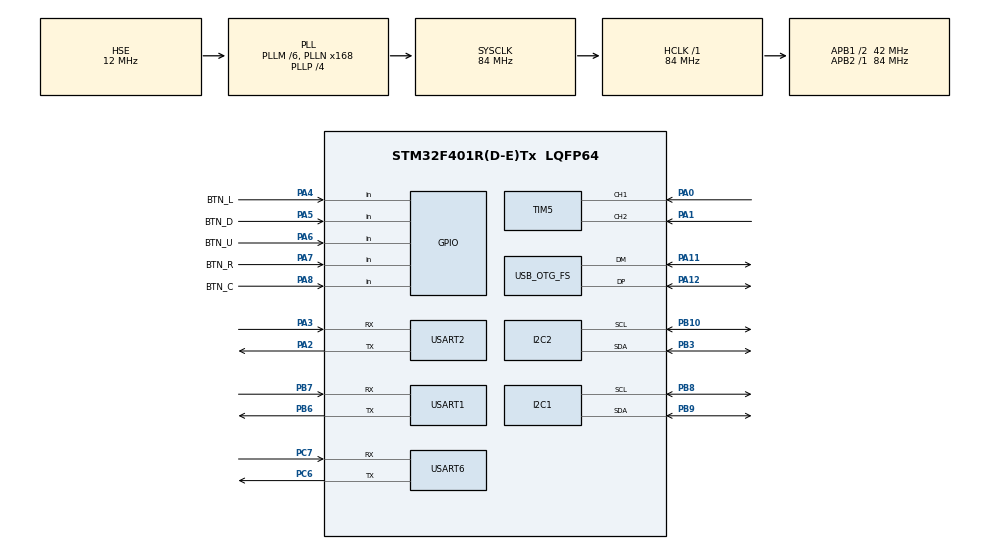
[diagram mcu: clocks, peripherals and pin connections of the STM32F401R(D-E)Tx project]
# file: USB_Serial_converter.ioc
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Dma.I2C1_RX.5.Direction=DMA_PERIPH_TO_MEMORY
Dma.I2C1_RX.5.FIFOMode=DMA_FIFOMODE_DISABLE
Dma.I2C1_RX.5.Instance=DMA1_Stream0
Dma.I2C1_RX.5.MemDataAlignment=DMA_MDATAALIGN_BYTE
Dma.I2C1_RX.5.MemInc=DMA_MINC_ENABLE
Dma.I2C1_RX.5.Mode=DMA_NORMAL
Dma.I2C1_RX.5.PeriphDataAlignment=DMA_PDATAALIGN_BYTE
Dma.I2C1_RX.5.PeriphInc=DMA_PINC_DISABLE
Dma.I2C1_RX.5.Priority=DMA_PRIORITY_LOW
Dma.I2C1_TX.0.Direction=DMA_MEMORY_TO_PERIPH
Dma.I2C1_TX.0.FIFOMode=DMA_FIFOMODE_DISABLE
Dma.I2C1_TX.0.Instance=DMA1_Stream6
Dma.I2C1_TX.0.MemDataAlignment=DMA_MDATAALIGN_BYTE
Dma.I2C1_TX.0.MemInc=DMA_MINC_ENABLE
Dma.I2C1_TX.0.Mode=DMA_NORMAL
Dma.I2C1_TX.0.PeriphDataAlignment=DMA_PDATAALIGN_BYTE
Dma.I2C1_TX.0.PeriphInc=DMA_PINC_DISABLE
Dma.I2C1_TX.0.Priority=DMA_PRIORITY_LOW
Dma.I2C2_RX.6.Direction=DMA_PERIPH_TO_MEMORY
Dma.I2C2_RX.6.FIFOMode=DMA_FIFOMODE_DISABLE
Dma.I2C2_RX.6.Instance=DMA1_Stream2
Dma.I2C2_RX.6.MemDataAlignment=DMA_MDATAALIGN_BYTE
Dma.I2C2_RX.6.MemInc=DMA_MINC_ENABLE
Dma.I2C2_RX.6.Mode=DMA_NORMAL
Dma.I2C2_RX.6.PeriphDataAlignment=DMA_PDATAALIGN_BYTE
Dma.I2C2_RX.6.PeriphInc=DMA_PINC_DISABLE
Dma.I2C2_RX.6.Priority=DMA_PRIORITY_LOW
Dma.I2C2_TX.1.Direction=DMA_MEMORY_TO_PERIPH
Dma.I2C2_TX.1.FIFOMode=DMA_FIFOMODE_DISABLE
Dma.I2C2_TX.1.Instance=DMA1_Stream7
Dma.I2C2_TX.1.MemDataAlignment=DMA_MDATAALIGN_BYTE
Dma.I2C2_TX.1.MemInc=DMA_MINC_ENABLE
Dma.I2C2_TX.1.Mode=DMA_NORMAL
Dma.I2C2_TX.1.PeriphDataAlignment=DMA_PDATAALIGN_BYTE
Dma.I2C2_TX.1.PeriphInc=DMA_PINC_DISABLE
Dma.I2C2_TX.1.Priority=DMA_PRIORITY_LOW
Dma.Request0=I2C1_TX
Dma.Request1=I2C2_TX
Dma.Request2=USART1_RX
Dma.Request3=USART2_RX
Dma.Request4=USART6_RX
Dma.Request5=I2C1_RX
Dma.Request6=I2C2_RX
Dma.USART1_RX.2.Direction=DMA_PERIPH_TO_MEMORY
Dma.USART1_RX.2.FIFOMode=DMA_FIFOMODE_DISABLE
Dma.USART1_RX.2.Instance=DMA2_Stream2
Dma.USART1_RX.2.MemDataAlignment=DMA_MDATAALIGN_BYTE
Dma.USART1_RX.2.MemInc=DMA_MINC_ENABLE
Dma.USART1_RX.2.Mode=DMA_CIRCULAR
Dma.USART1_RX.2.PeriphDataAlignment=DMA_PDATAALIGN_BYTE
Dma.USART1_RX.2.PeriphInc=DMA_PINC_DISABLE
Dma.USART1_RX.2.Priority=DMA_PRIORITY_LOW
Dma.USART2_RX.3.Direction=DMA_PERIPH_TO_MEMORY
Dma.USART2_RX.3.FIFOMode=DMA_FIFOMODE_DISABLE
Dma.USART2_RX.3.Instance=DMA1_Stream5
Dma.USART2_RX.3.MemDataAlignment=DMA_MDATAALIGN_BYTE
Dma.USART2_RX.3.MemInc=DMA_MINC_ENABLE
Dma.USART2_RX.3.Mode=DMA_CIRCULAR
Dma.USART2_RX.3.PeriphDataAlignment=DMA_PDATAALIGN_BYTE
Dma.USART2_RX.3.PeriphInc=DMA_PINC_DISABLE
Dma.USART2_RX.3.Priority=DMA_PRIORITY_LOW
Dma.USART6_RX.4.Direction=DMA_PERIPH_TO_MEMORY
Dma.USART6_RX.4.FIFOMode=DMA_FIFOMODE_DISABLE
Dma.USART6_RX.4.Instance=DMA2_Stream1
Dma.USART6_RX.4.MemDataAlignment=DMA_MDATAALIGN_BYTE
Dma.USART6_RX.4.MemInc=DMA_MINC_ENABLE
Dma.USART6_RX.4.Mode=DMA_CIRCULAR
Dma.USART6_RX.4.PeriphDataAlignment=DMA_PDATAALIGN_BYTE
Dma.USART6_RX.4.PeriphInc=DMA_PINC_DISABLE
Dma.USART6_RX.4.Priority=DMA_PRIORITY_LOW
I2C1.DutyCycle=I2C_DUTYCYCLE_2
I2C1.I2C_Mode=I2C_Fast
I2C2.I2C_Mode=I2C_Fast
Mcu.Family=STM32F4
Mcu.Name=STM32F401R(D-E)Tx
Mcu.Package=LQFP64
NVIC.DMA1_Stream0_IRQn=true\:0\:0\:false\:false\:true\:false\:true\:true
NVIC.DMA1_Stream2_IRQn=true\:0\:0\:false\:false\:true\:false\:true\:true
NVIC.DMA1_Stream5_IRQn=true\:0\:0\:false\:false\:true\:false\:true\:true
NVIC.DMA1_Stream6_IRQn=true\:0\:0\:false\:false\:true\:false\:true\:true
NVIC.DMA1_Stream7_IRQn=true\:0\:0\:false\:false\:true\:false\:true\:true
NVIC.DMA2_Stream1_IRQn=true\:0\:0\:false\:false\:true\:false\:true\:true
NVIC.DMA2_Stream2_IRQn=true\:0\:0\:false\:false\:true\:false\:true\:true
NVIC.I2C1_ER_IRQn=true\:6\:0\:true\:false\:true\:true\:true\:true
NVIC.I2C1_EV_IRQn=true\:6\:0\:true\:false\:true\:true\:true\:true
NVIC.I2C2_ER_IRQn=true\:6\:0\:true\:false\:true\:true\:true\:true
NVIC.I2C2_EV_IRQn=true\:6\:0\:true\:false\:true\:true\:true\:true
NVIC.OTG_FS_IRQn=true\:0\:0\:false\:false\:true\:false\:true\:true
NVIC.PriorityGroup=NVIC_PRIORITYGROUP_4
NVIC.USART1_IRQn=true\:6\:0\:true\:false\:true\:true\:true\:true
NVIC.USART2_IRQn=true\:6\:0\:true\:false\:true\:true\:true\:true
NVIC.USART6_IRQn=true\:6\:0\:true\:false\:true\:true\:true\:true
PA0-WKUP.Signal=S_TIM5_CH1
PA1.Signal=S_TIM5_CH2
PA11.Mode=Device_Only
PA11.Signal=USB_OTG_FS_DM
PA12.Mode=Device_Only
PA12.Signal=USB_OTG_FS_DP
PA13.Mode=Serial_Wire
PA13.Signal=SYS_JTMS-SWDIO
PA14.Mode=Serial_Wire
PA14.Signal=SYS_JTCK-SWCLK
PA2.Mode=Asynchronous
PA2.Signal=USART2_TX
PA3.Mode=Asynchronous
PA3.Signal=USART2_RX
PA4.GPIO_Label=BTN_L
PA4.Signal=GPIO_Input
PA5.GPIO_Label=BTN_D
PA5.Signal=GPIO_Input
PA6.GPIO_Label=BTN_U
PA6.Signal=GPIO_Input
PA7.GPIO_Label=BTN_R
PA7.Signal=GPIO_Input
PA8.GPIO_Label=BTN_C
PA8.Signal=GPIO_Input
PB10.GPIO_Pu=GPIO_PULLUP
PB10.Mode=I2C
PB10.Signal=I2C2_SCL
PB3.GPIO_Pu=GPIO_PULLUP
PB3.Mode=I2C
PB3.Signal=I2C2_SDA
PB6.Mode=Asynchronous
PB6.Signal=USART1_TX
PB7.Mode=Asynchronous
PB7.Signal=USART1_RX
PB8.GPIO_Pu=GPIO_PULLUP
PB8.Mode=I2C
PB8.Signal=I2C1_SCL
PB9.GPIO_Pu=GPIO_PULLUP
PB9.Mode=I2C
PB9.Signal=I2C1_SDA
PC6.Mode=Asynchronous
PC6.Signal=USART6_TX
PC7.Mode=Asynchronous
PC7.Signal=USART6_RX
PH0\ -\ OSC_IN.Mode=HSE-External-Oscillator
PH0\ -\ OSC_IN.Signal=RCC_OSC_IN
PH1\ -\ OSC_OUT.Mode=HSE-External-Oscillator
PH1\ -\ OSC_OUT.Signal=RCC_OSC_OUT
ProjectManager.HeapSize=0x200
ProjectManager.StackSize=0x400
ProjectManager.TargetToolchain=STM32CubeIDE
RCC.48MHZClocksFreq_Value=48000000
RCC.AHBFreq_Value=84000000
RCC.APB1CLKDivider=RCC_HCLK_DIV2
RCC.APB1Freq_Value=42000000
RCC.APB1TimFreq_Value=84000000
RCC.APB2Freq_Value=84000000
RCC.APB2TimFreq_Value=84000000
RCC.CortexFreq_Value=84000000
RCC.HCLKFreq_Value=84000000
RCC.HSE_VALUE=12000000
RCC.HSI_VALUE=16000000
RCC.LSE_VALUE=32768
RCC.PLLM=6
RCC.PLLN=168
RCC.PLLP=RCC_PLLP_DIV4
RCC.PLLQ=7
RCC.SYSCLKFreq_VALUE=84000000
RCC.SYSCLKSource=RCC_SYSCLKSOURCE_PLLCLK
RCC.VCOOutputFreq_Value=336000000
SH.S_TIM5_CH1.0=TIM5_CH1,Encoder_Interface
SH.S_TIM5_CH2.0=TIM5_CH2,Encoder_Interface
TIM5.EncoderMode=TIM_ENCODERMODE_TI1
USART1.OverSampling=UART_OVERSAMPLING_8
USART1.VirtualMode=VM_ASYNC
USART2.OverSampling=UART_OVERSAMPLING_8
USART2.VirtualMode=VM_ASYNC
USART6.OverSampling=UART_OVERSAMPLING_8
USART6.VirtualMode=VM_ASYNC
USB_DEVICE.APP_TX_DATA_SIZE-CDC_FS=64
USB_DEVICE.CLASS_NAME_FS=CDC
USB_DEVICE.VirtualMode-CDC_FS=Cdc
USB_DEVICE.VirtualModeFS=Cdc_FS
USB_OTG_FS.VirtualMode=Device_Only
VP_USB_DEVICE_VS_USB_DEVICE_CDC_FS.Mode=CDC_FS
board=custom

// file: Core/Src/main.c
/* USER CODE BEGIN Header */
/**
  ******************************************************************************
  * @file           : main.c
  * @brief          : Main program body
  ******************************************************************************
  * @attention
  *
  * Copyright (c) 2026 STMicroelectronics.
  * All rights reserved.
  *
  * This software is licensed under terms that can be found in the LICENSE file
  * in the root directory of this software component.
  * If no LICENSE file comes with this software, it is provided AS-IS.
  *
  ******************************************************************************
  */
/* USER CODE END Header */
#include "main.h"
#include "dma.h"
#include "i2c.h"
#include "tim.h"
#include "usart.h"
#include "usb_device.h"
#include "gpio.h"

/* USER CODE BEGIN Includes */
#include "UserMain.hpp"

/* USER CODE END Includes */

void SystemClock_Config(void);

int main(void)
{

  /* MCU Configuration--------------------------------------------------------*/

  /* Reset of all peripherals, Initializes the Flash interface and the Systick. */
  HAL_Init();

  /* Configure the system clock */
  SystemClock_Config();

  /* Initialize all configured peripherals */
  MX_GPIO_Init();
  MX_DMA_Init();
  MX_I2C1_Init();
  MX_I2C2_Init();
  MX_TIM5_Init();
  MX_USART1_UART_Init();
  MX_USART2_UART_Init();
  MX_USART6_UART_Init();
  MX_USB_DEVICE_Init();
  /* USER CODE BEGIN 2 */
  setup();

  /* USER CODE END 2 */

  /* Infinite loop */
  /* USER CODE BEGIN WHILE */
  while (1)
  {
    loop();
    /* USER CODE END WHILE */

  }
}

void SystemClock_Config(void)
{
  RCC_OscInitTypeDef RCC_OscInitStruct = {0};
  RCC_ClkInitTypeDef RCC_ClkInitStruct = {0};

  /** Configure the main internal regulator output voltage
  */
  __HAL_RCC_PWR_CLK_ENABLE();
  __HAL_PWR_VOLTAGESCALING_CONFIG(PWR_REGULATOR_VOLTAGE_SCALE2);

  /** Initializes the RCC Oscillators according to the specified parameters
  * in the RCC_OscInitTypeDef structure.
  */
  RCC_OscInitStruct.OscillatorType = RCC_OSCILLATORTYPE_HSE;
  RCC_OscInitStruct.HSEState = RCC_HSE_ON;
  RCC_OscInitStruct.PLL.PLLState = RCC_PLL_ON;
  RCC_OscInitStruct.PLL.PLLSource = RCC_PLLSOURCE_HSE;
  RCC_OscInitStruct.PLL.PLLM = 6;
  RCC_OscInitStruct.PLL.PLLN = 168;
  RCC_OscInitStruct.PLL.PLLP = RCC_PLLP_DIV4;
  RCC_OscInitStruct.PLL.PLLQ = 7;
  if (HAL_RCC_OscConfig(&RCC_OscInitStruct) != HAL_OK)
  {
    Error_Handler();
  }

  /** Initializes the CPU, AHB and APB buses clocks
  */
  RCC_ClkInitStruct.ClockType = RCC_CLOCKTYPE_HCLK|RCC_CLOCKTYPE_SYSCLK
                              |RCC_CLOCKTYPE_PCLK1|RCC_CLOCKTYPE_PCLK2;
  RCC_ClkInitStruct.SYSCLKSource = RCC_SYSCLKSOURCE_PLLCLK;
  RCC_ClkInitStruct.AHBCLKDivider = RCC_SYSCLK_DIV1;
  RCC_ClkInitStruct.APB1CLKDivider = RCC_HCLK_DIV2;
  RCC_ClkInitStruct.APB2CLKDivider = RCC_HCLK_DIV1;

  if (HAL_RCC_ClockConfig(&RCC_ClkInitStruct, FLASH_LATENCY_2) != HAL_OK)
  {
    Error_Handler();
  }
}

void Error_Handler(void)
{
  __disable_irq();
  while (1)
  {
  }
}
